# liliumFP1_secure register map
Vendor: Nordic Semiconductor; Series: liliumFP1; File version: 1
CPU: CM33 r0p4, little endian, MPU, FPU, 3 interrupt priority bits, 480 interrupts
Registers are 32-bit, read-write, reset 0x0 unless marked. A register's access mark holds for its fields unless they carry their own. Offsets are from the block's base; [hi:lo] are bit positions; lines under a group give offsets from that group; {n}, {i} and the like mark numbered series.

## IPCMAP_S — IPCMAP APB registers
Base 0x5F923000
{0x400+8i} CHANNEL[{i}] (i=0..15) group — Unspecified
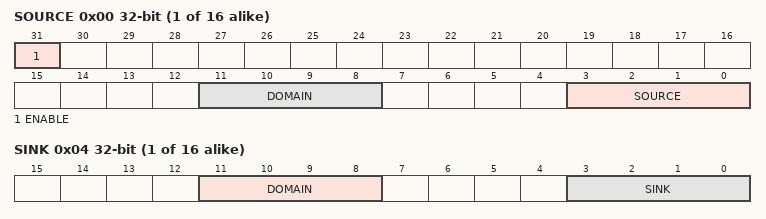
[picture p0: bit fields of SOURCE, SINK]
  0x00 SOURCE — Description cluster: The IPCT source configuration for the channel [n] from a ICPT.
    [31] ENABLE — Channel enable.
      0=Disabled (Disable channel.); 1=Enabled (Enable channel.)
    [11:8] DOMAIN — Domain identifier.
    [3:0] SOURCE — Source identification for IPC mapping.
  0x04 SINK — Description cluster: The IPCT sink configuration for the channel [n] to another ICPT.
    [11:8] DOMAIN — Domain identifier.
    [3:0] SINK — Sink identifiation for IPC mapping.

## IRQMAP_S — IRQMAP APB registers
Base 0x5F924000
{0x400+4i} IRQ[{i}] (i=0..479) group — Unspecified
  0x00 SINK — Description cluster: The interrupt sink configuration for interrupt [n] to a processor.
    [11:8] PROCESSORID — Processor identifier.

## GLOBAL_EGU130_NS — Event generator unit 0
Base 0x4F92D000
Same registers: GLOBAL_EGU130_S 0x5F92D000
{0x0+4i} TASKS_TRIGGER[{i}] (i=0..15) wo — Description collection: Trigger n for triggering the corresponding TRIGGERED[n] event
  [0] TASKS_TRIGGER — Trigger n for triggering the corresponding TRIGGERED[n] event
    1=Trigger task
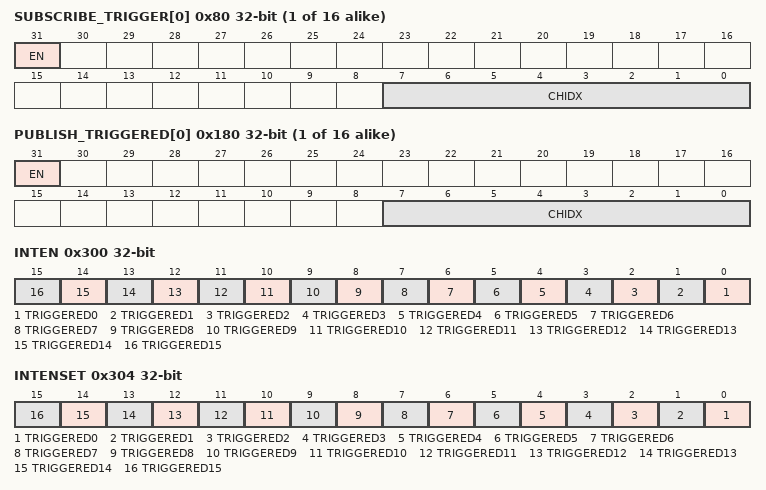
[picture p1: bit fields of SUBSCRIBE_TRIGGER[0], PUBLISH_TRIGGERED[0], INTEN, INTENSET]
{0x80+4i} SUBSCRIBE_TRIGGER[{i}] (i=0..15) — Description collection: Subscribe configuration for task TRIGGER[n]
  [31] EN
    0=Disabled (Disable subscription); 1=Enabled (Enable subscription)
  [7:0] CHIDX — DPPI channel that task TRIGGER[n] will subscribe to
{0x100+4i} EVENTS_TRIGGERED[{i}] (i=0..15) — Description collection: Event number n generated by triggering the corresponding TRIGGER[n] task
  [0] EVENTS_TRIGGERED — Event number n generated by triggering the corresponding TRIGGER[n] task
    0=NotGenerated (Event not generated); 1=Generated (Event generated)
{0x180+4i} PUBLISH_TRIGGERED[{i}] (i=0..15) — Description collection: Publish configuration for event TRIGGERED[n]
  [31] EN
    0=Disabled (Disable publishing); 1=Enabled (Enable publishing)
  [7:0] CHIDX — DPPI channel that event TRIGGERED[n] will publish to
0x300 INTEN — Enable or disable interrupt
  [all] fields
    0=Disabled; 1=Enabled
  [n] TRIGGERED{n} (n=0..15) — Enable or disable interrupt for event TRIGGERED[{n}]
0x304 INTENSET — Enable interrupt
  [all] fields
    on read: 0=Disabled (Read: Disabled); 1=Enabled (Read: Enabled) | on write: 1=Set (Enable)
  [n] TRIGGERED{n} (n=0..15) — Write '1' to enable interrupt for event TRIGGERED[{n}]
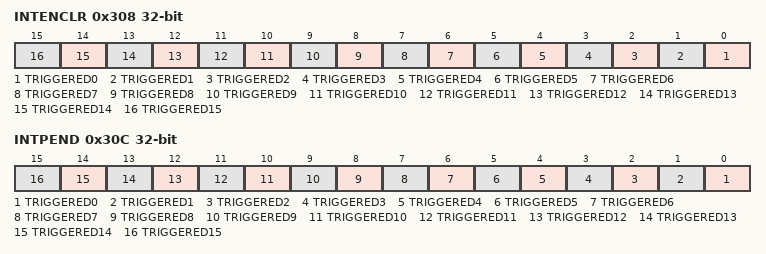
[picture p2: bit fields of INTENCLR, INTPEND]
0x308 INTENCLR — Disable interrupt
  [all] fields
    on read: 0=Disabled (Read: Disabled); 1=Enabled (Read: Enabled) | on write: 1=Clear (Disable)
  [n] TRIGGERED{n} (n=0..15) — Write '1' to disable interrupt for event TRIGGERED[{n}]
0x30C INTPEND ro — Pending interrupts
  [all] fields
    on read: 0=NotPending (Read: Not pending); 1=Pending (Read: Pending)
  [n] TRIGGERED{n} (n=0..15) — Read pending status of interrupt for event TRIGGERED[{n}]

## GLOBAL_GPIOINTERNAL_NS — GPIO Internal 0
Base 0x4F939E00
Same registers: GLOBAL_GPIOINTERNAL_S 0x5F939E00
0x40 LATCHCLRWAITCNT reset 0x2 — Select the number of wait cycles inserted on the bus when a LATCH register is cleared.
  [1:0] LATCHCLRWAITCNT
0x44 FORCELDETECTLOWCNT reset 0x8 — Select the number of cycles that LDETECT is forced low after clearing a LATCH register.
  [3:0] FORCELDETECTLOWCNT
0x48 RESET — Reset all GPIO registers.
  [0] RESET
    1=RESET (Trigger reset); 0=NA (No effect)
0x4C SENSECONFIGCHANGECNT reset 0x3 — Selects the number of cycles before the SENSE configuration takes effect when it is changed. Setting this register lower than the reset value can lead to unwanted LATCH set when SENSE and INPUT fields (PIN[n].CNF) are changed simultaneously.
  [2:0] SENSECONFIGCHANGECNT — Selects the number of cycles before the SENSE configuration takes effect when it is changed.
0x50 PCGC group — Unspecified
  0x00 TRIGZEROPENALTY ro — Trigger zero penalty
    [0] TRIGGER
      1=Enable (Trigger zero penalty)
  0x04 TRIGFULLPENALTY ro — Trigger full penalty
    [0] TRIGGER
      1=Enable (Trigger full penalty)
  {0x8+4j} PENALTY[{j}] (j=0..1) ro — Description collection: Penalty level for power/clock pair n
    [7:0] PENALTY — Penalty level
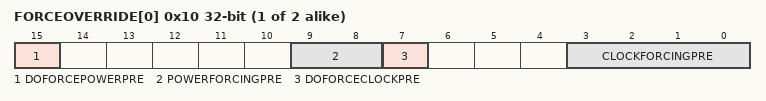
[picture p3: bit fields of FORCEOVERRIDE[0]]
  {0x10+4j} FORCEOVERRIDE[{j}] (j=0..1) ro — Description collection: Force override of power/clock pair n
    [15] DOFORCEPOWERPRE, [9:8] POWERFORCINGPRE, [7] DOFORCECLOCKPRE, [3:0] CLOCKFORCINGPRE
